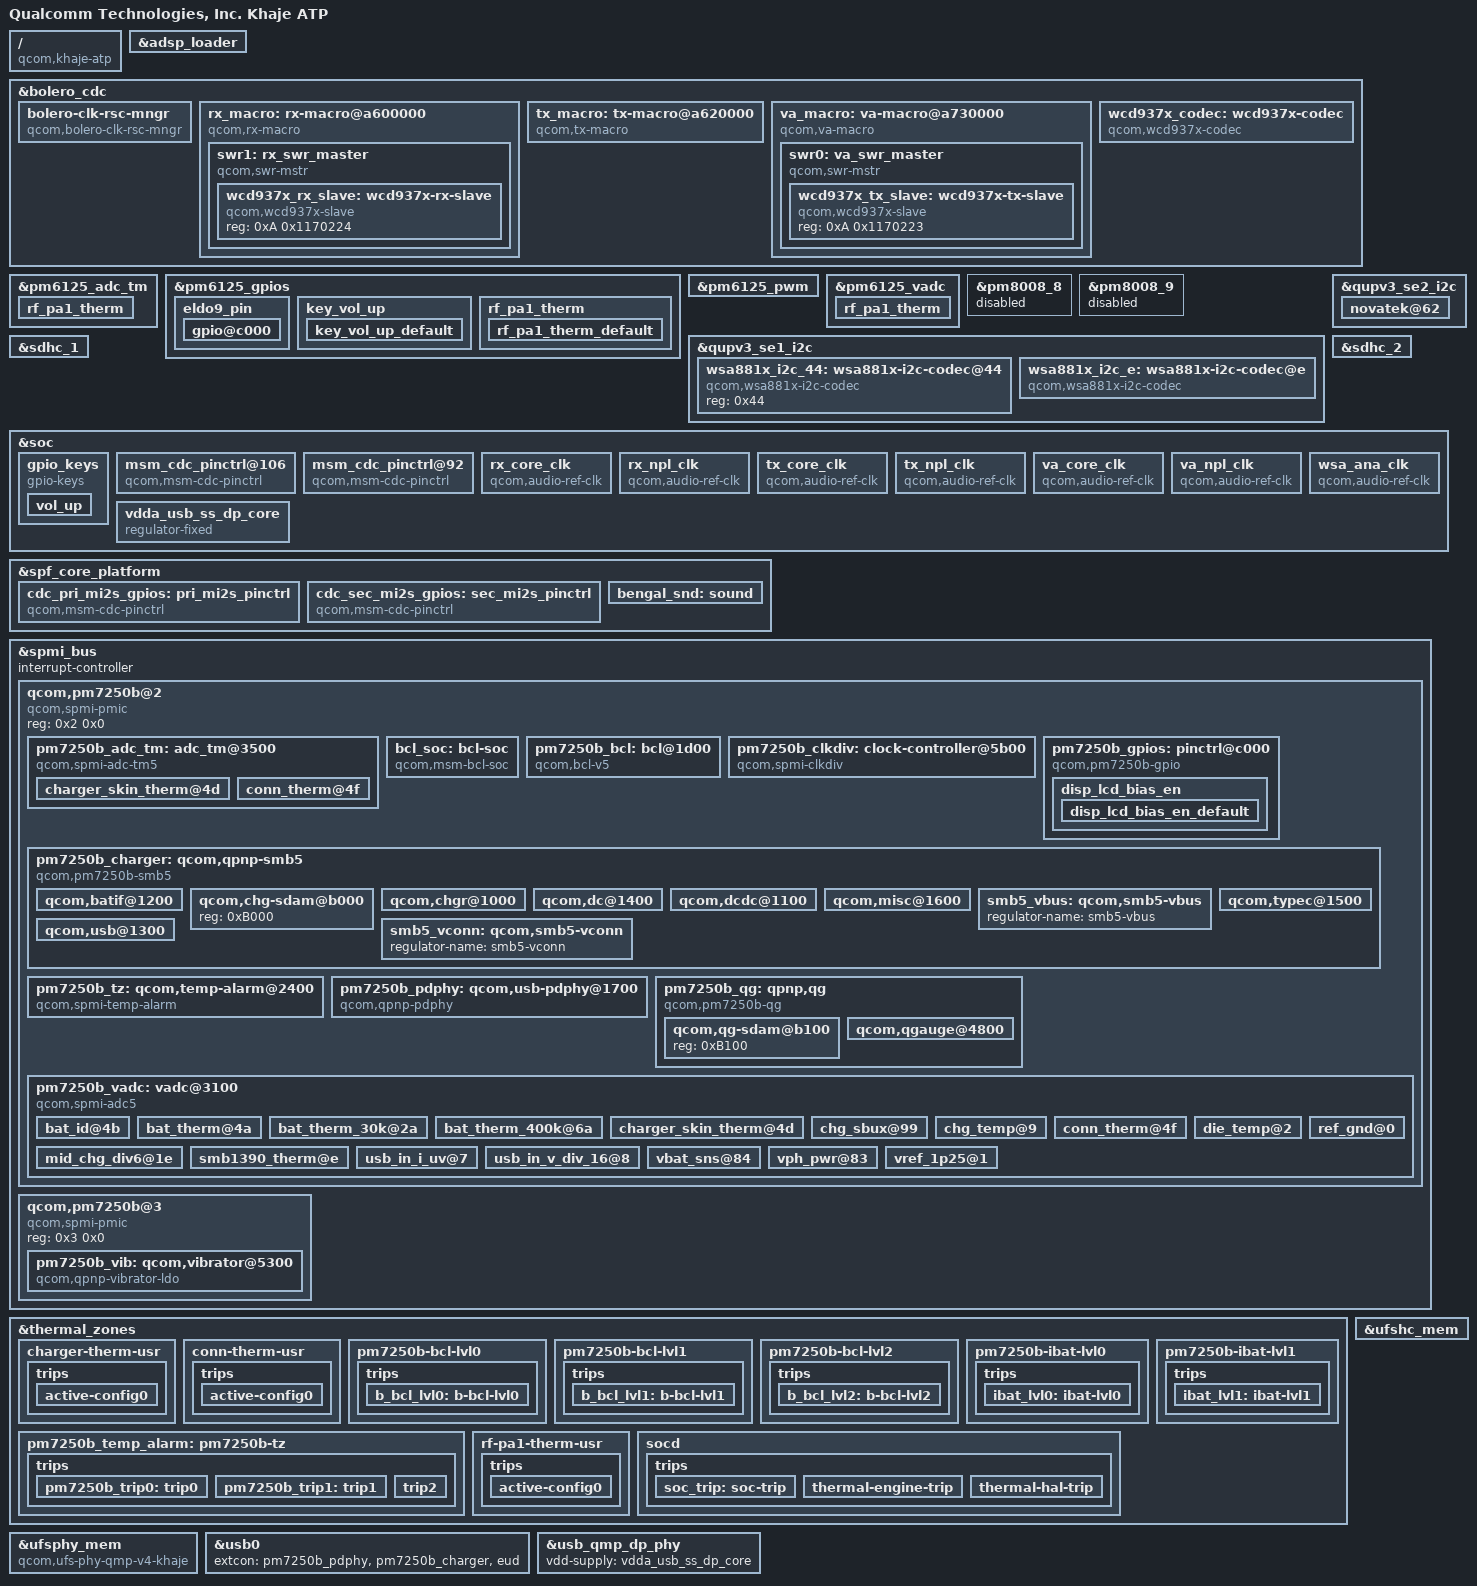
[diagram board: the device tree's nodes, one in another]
/dts-v1/;

/ {
    compatible = "qcom,khaje-atp", "qcom,khaje", "qcom,atp";
    model = "Qualcomm Technologies, Inc. Khaje ATP";
    qcom,board-id = <0x21 0x0>;
    qcom,msm-id = <0x24A 0x10000>;
    qcom,pmic-id = <0x2D 0x2E 0x0 0x0>;
};

&adsp_loader {
    adsp-fw-bit-values = <0x1>;
    adsp-fw-names = "adsp2";
    nvmem-cell-names = "adsp_variant";
    nvmem-cells = <&adsp_variant>;
};

&bolero_cdc {
    qcom,bolero-version = <0x5>;
    qcom,num-macros = <0x3>;
    bolero-clk-rsc-mngr {
        clock-names = "tx_core_clk", "tx_npl_clk", "rx_core_clk", "rx_npl_clk", "va_core_clk", "va_npl_clk";
        clocks = <&clock_audio_tx_1 0x0 &clock_audio_tx_2 0x0 &clock_audio_rx_1 0x0 &clock_audio_rx_2 0x0 &clock_audio_va_1 0x0 &clock_audio_va_2 0x0>;
        compatible = "qcom,bolero-clk-rsc-mngr";
        qcom,fs-gen-sequence = <0x3000 0x1 0x1 0x3004 0x3 0x3 0x3004 0x3 0x1 0x3080 0x2 0x2>;
        qcom,rx_mclk_mode_muxsel = <0xA5640D8>;
        qcom,va_mclk_mode_muxsel = "\nz";
    };
    rx_macro: rx-macro@a600000 {
        clock-names = "rx_core_clk", "rx_npl_clk";
        clocks = <&clock_audio_rx_1 0x0 &clock_audio_rx_2 0x0>;
        compatible = "qcom,rx-macro";
        qcom,default-clk-id = <0x0>;
        qcom,rx-bcl-pmic-params = [00 04 3E];
        qcom,rx-swr-gpios = <&rx_swr_gpios>;
        qcom,rx_mclk_mode_muxsel = <0xA5640D8>;
        reg = <0xA600000 0x0>;
        swr1: rx_swr_master {
            #address-cells = <0x2>;
            #size-cells = <0x0>;
            clock-names = "lpass_audio_hw_vote";
            clocks = <&lpass_audio_hw_vote 0x0>;
            compatible = "qcom,swr-mstr";
            interrupt-names = "swr_master_irq";
            interrupts = <0x0 0x129 0x4>;
            qcom,disable-div2-clk-switch = <0x1>;
            qcom,mipi-sdw-block-packing-mode = <0x1>;
            qcom,swr-clock-stop-mode0 = <0x1>;
            qcom,swr-master-version = <0x1060000>;
            qcom,swr-num-dev = <0x1>;
            qcom,swr-num-ports = <0x5>;
            qcom,swr-port-mapping = <0x1 0xE 0x1 0x1 0xF 0x2 0x2 0x12 0x1 0x3 0x10 0x1 0x3 0x11 0x2 0x4 0x13 0x1 0x5 0x14 0x1 0x5 0x15 0x2>;
            qcom,swr_master_id = <0x2>;
            qcom,swrm-hctl-reg = <0xA6A9098>;
            swrm-io-base = <0xA610000 0x0>;
            wcd937x_rx_slave: wcd937x-rx-slave {
                compatible = "qcom,wcd937x-slave";
                reg = <0xA 0x1170224>;
            };
        };
    };
    tx_macro: tx-macro@a620000 {
        clock-names = "tx_core_clk", "tx_npl_clk";
        clocks = <&clock_audio_tx_1 0x0 &clock_audio_tx_2 0x0>;
        compatible = "qcom,tx-macro";
        qcom,is-used-swr-gpio = <0x0>;
        qcom,tx-dmic-sample-rate = <0x249F00>;
        reg = <0xA620000 0x0>;
    };
    va_macro: va-macro@a730000 {
        clock-names = "lpass_audio_hw_vote";
        clocks = <&lpass_audio_hw_vote 0x0>;
        compatible = "qcom,va-macro";
        qcom,default-clk-id = <0x0>;
        qcom,is-used-swr-gpio = <0x1>;
        qcom,va-clk-mux-select = <0x1>;
        qcom,va-dmic-sample-rate = <0x927C0>;
        qcom,va-island-mode-muxsel = "\nz";
        qcom,va-swr-gpios = <&va_swr_gpios>;
        reg = <0xA730000 0x0>;
        swr0: va_swr_master {
            #address-cells = <0x2>;
            #size-cells = <0x0>;
            clock-names = "lpass_audio_hw_vote";
            clocks = <&lpass_audio_hw_vote 0x0>;
            compatible = "qcom,swr-mstr";
            interrupt-names = "swr_master_irq", "swr_wake_irq";
            interrupts = <0x0 0x128 0x4 0x0 0x4F 0x4>;
            qcom,is-always-on = <0x1>;
            qcom,mipi-sdw-block-packing-mode = <0x1>;
            qcom,swr-clock-stop-mode0 = <0x1>;
            qcom,swr-master-version = <0x1060000>;
            qcom,swr-mstr-irq-wakeup-capable = <0x1>;
            qcom,swr-num-dev = <0x1>;
            qcom,swr-num-ports = <0x3>;
            qcom,swr-port-mapping = <0x1 0x2E 0x1 0x1 0x2F 0x2 0x1 0x30 0x4 0x1 0x31 0x8 0x2 0x32 0x1 0x2 0x33 0x2 0x2 0x34 0x4 0x2 0x35 0x8 0x3 0x36 0x1 0x3 0x37 0x2 0x3 0x38 0x4 0x3 0x39 0x8>;
            qcom,swr-wakeup-required = <0x1>;
            qcom,swr_master_id = <0x3>;
            qcom,swrm-hctl-reg = <0xA7EC100>;
            swrm-io-base = <0xA740000 0x0>;
            wcd937x_tx_slave: wcd937x-tx-slave {
                compatible = "qcom,wcd937x-slave";
                reg = <0xA 0x1170223>;
            };
        };
    };
    wcd937x_codec: wcd937x-codec {
        cdc-vdd-buck-supply = <&L14A>;
        cdc-vdd-rxtx-supply = <&L9A>;
        cdc-vddpx-supply = <&L9A>;
        compatible = "qcom,wcd937x-codec";
        qcom,cdc-micbias1-mv = <0x708>;
        qcom,cdc-micbias2-mv = <0x708>;
        qcom,cdc-micbias3-mv = <0x708>;
        qcom,cdc-on-demand-supplies = "cdc-vdd-buck";
        qcom,cdc-static-supplies = "cdc-vdd-rxtx", "cdc-vddpx";
        qcom,cdc-vdd-buck-current = <0x9EB10>;
        qcom,cdc-vdd-buck-voltage = <0x1B7740 0x1B7740>;
        qcom,cdc-vdd-rxtx-current = <0x2710>;
        qcom,cdc-vdd-rxtx-voltage = <0x1B7740 0x1B7740>;
        qcom,cdc-vddpx-current = <0x4E20>;
        qcom,cdc-vddpx-voltage = <0x1B7740 0x1B7740>;
        qcom,rx-slave = <&wcd937x_rx_slave>;
        qcom,rx_swr_ch_map = <0x0 0xE 0x1 0x0 0xE 0x0 0xF 0x2 0x0 0xF 0x1 0x12 0x1 0x0 0x12 0x2 0x10 0x1 0x0 0x10 0x2 0x11 0x2 0x0 0x11 0x3 0x13 0x1 0x0 0x13 0x4 0x14 0x1 0x0 0x14 0x4 0x15 0x2 0x0 0x15>;
        qcom,split-codec = <0x1>;
        qcom,swr-tx-port-params = <0x1 0x0 0x0 0x1 0x1 0x0 0x1 0x0 0x0 0x1 0x1 0x0 0x1 0x0 0x1 0x0 0x0 0x1 0x2 0x0 0x1 0x0 0x2 0x0 0x1 0x0 0x1 0x0 0x1 0x0 0x1 0x0>;
        qcom,tx-slave = <&wcd937x_tx_slave>;
        qcom,tx_swr_ch_map = <0x0 0x1E 0x1 0x493E00 0x2E 0x1 0x1F 0x1 0x493E00 0x32 0x1 0x20 0x2 0x493E00 0x33 0x2 0x22 0x1 0x0 0x31 0x2 0x23 0x2 0x0 0x32 0x2 0x1D 0x4 0x493E00 0x33 0x3 0x24 0x1 0x0 0x34 0x3 0x25 0x2 0x0 0x35 0x3 0x26 0x4 0x0 0x36 0x3 0x27 0x8 0x0 0x37>;
        qcom,wcd-rst-gpio-node = <&wcd937x_rst_gpio>;
    };
};

&pm6125_adc_tm {
    status = "ok";
    rf_pa1_therm {
        io-channels = <&pm6125_vadc 0x55>;
        qcom,hw-settle-time-us = <0xC8>;
        qcom,ratiometric;
        reg = <0x3>;
    };
};

&pm6125_gpios {
    eldo9_pin {
        gpio@c000 {
            bias-disable;
            function = "normal";
            output-high;
            pins = "gpio1";
            power-source = <0x0>;
            qcom,drive-strength = <0x2>;
        };
    };
    key_vol_up {
        key_vol_up_default: key_vol_up_default {
            bias-pull-up;
            function = "normal";
            input-enable;
            pins = "gpio5";
            power-source = <0x0>;
        };
    };
    rf_pa1_therm {
        rf_pa1_therm_default: rf_pa1_therm_default {
            bias-high-impedance;
            pins = "gpio7";
        };
    };
};

&pm6125_pwm {
    status = "okay";
};

&pm6125_vadc {
    pinctrl-0 = <&camera_therm_default &emmc_therm_default &rf_pa1_therm_default>;
    rf_pa1_therm {
        label = "rf_pa1_therm";
        qcom,hw-settle-time = <0xC8>;
        qcom,pre-scaling = <0x1 0x1>;
        qcom,ratiometric;
        reg = <0x55>;
    };
};

&pm8008_8 {
    status = "disabled";
};

&pm8008_9 {
    status = "disabled";
};

&qupv3_se1_i2c {
    wsa881x_i2c_44: wsa881x-i2c-codec@44 {
        compatible = "qcom,wsa881x-i2c-codec";
        reg = <0x44>;
    };
    wsa881x_i2c_e: wsa881x-i2c-codec@e {
        clock-names = "wsa_mclk";
        clocks = <&wsa881x_analog_clk 0x0>;
        compatible = "qcom,wsa881x-i2c-codec";
        qcom,wsa-analog-clk-gpio = <&wsa881x_analog_clk_gpio>;
        qcom,wsa-analog-reset-gpio = <&wsa881x_analog_reset_gpio>;
        qcom,wsa-prefix = "SpkrMono";
        reg = <0xE>;
    };
};

&qupv3_se2_i2c {
    status = "okay";
    novatek@62 {
        interrupt-parent = <&tlmm>;
        interrupts = <0x50 0x2008>;
        novatek,irq-gpio = <&tlmm 0x50 0x2008>;
        novatek,reset-gpio = <&tlmm 0x56 0x0>;
        pinctrl-0 = <&ts_int_active &ts_reset_active>;
        pinctrl-1 = <&ts_int_suspend &ts_reset_suspend>;
        pinctrl-2 = <&ts_release>;
        pinctrl-names = "pmx_ts_active", "pmx_ts_suspend", "pmx_ts_release";
        reg = <0x62>;
        status = "ok";
    };
};

&sdhc_1 {
    pinctrl-0 = <&sdc1_on>;
    pinctrl-1 = <&sdc1_off>;
    pinctrl-names = "active", "sleep";
    qcom,vdd-current-level = <0x0 0x8B290>;
    qcom,vdd-io-always-on;
    qcom,vdd-io-current-level = <0x0 0x4F588>;
    qcom,vdd-io-lpm-sup;
    qcom,vdd-io-voltage-level = <0x1B7740 0x1B7740>;
    qcom,vdd-voltage-level = <0x2D2A80 0x2D2A80>;
    status = "ok";
    vdd-io-supply = <&L11A>;
    vdd-supply = <&L24A>;
};

&sdhc_2 {
    cd-gpios = <&tlmm 0x58 0x1>;
    pinctrl-0 = <&sdc2_on>;
    pinctrl-1 = <&sdc2_off>;
    pinctrl-names = "active", "sleep";
    qcom,vdd-current-level = <0x0 0xC3500>;
    qcom,vdd-io-bias-current-level = <0x0 0x1770>;
    qcom,vdd-io-bias-voltage-level = <0x132A40 0x132A40>;
    qcom,vdd-io-current-level = <0x0 0x55F0>;
    qcom,vdd-io-voltage-level = <0x1B7740 0x2D2A80>;
    qcom,vdd-voltage-level = <0x2D2A80 0x2D2A80>;
    status = "ok";
    vdd-io-bias-supply = <&L7A>;
    vdd-io-supply = <&L5A>;
    vdd-supply = <&L22A>;
};

&soc {
    gpio_keys {
        compatible = "gpio-keys";
        label = "gpio-keys";
        pinctrl-0 = <&key_vol_up_default>;
        pinctrl-names = "default";
        vol_up {
            debounce-interval = <0xF>;
            gpio-key,wakeup;
            gpios = <&pm6125_gpios 0x5 0x1>;
            label = "volume_up";
            linux,can-disable;
            linux,code = <0x73>;
            linux,input-type = <0x1>;
        };
    };
    msm_cdc_pinctrl@106 {
        #gpio-cells = <0x0>;
        compatible = "qcom,msm-cdc-pinctrl";
        pinctrl-0 = <&spkr_1_sd_n_active>;
        pinctrl-1 = <&spkr_1_sd_n_sleep>;
        pinctrl-names = "aud_active", "aud_sleep";
    };
    msm_cdc_pinctrl@92 {
        #gpio-cells = <0x0>;
        compatible = "qcom,msm-cdc-pinctrl";
        pinctrl-0 = <&wcd937x_reset_active>;
        pinctrl-1 = <&wcd937x_reset_sleep>;
        pinctrl-names = "aud_active", "aud_sleep";
    };
    rx_core_clk {
        #clock-cells = <0x1>;
        compatible = "qcom,audio-ref-clk";
        qcom,codec-ext-clk-src = <0x5>;
        qcom,codec-lpass-clk-id = <0x30E>;
        qcom,codec-lpass-ext-clk-freq = <0x1588800>;
    };
    rx_npl_clk {
        #clock-cells = <0x1>;
        compatible = "qcom,audio-ref-clk";
        qcom,codec-ext-clk-src = <0x6>;
        qcom,codec-lpass-clk-id = <0x30F>;
        qcom,codec-lpass-ext-clk-freq = <0x1588800>;
    };
    tx_core_clk {
        #clock-cells = <0x1>;
        compatible = "qcom,audio-ref-clk";
        qcom,codec-ext-clk-src = <0x7>;
        qcom,codec-lpass-clk-id = <0x30C>;
        qcom,codec-lpass-ext-clk-freq = <0x124F800>;
    };
    tx_npl_clk {
        #clock-cells = <0x1>;
        compatible = "qcom,audio-ref-clk";
        qcom,codec-ext-clk-src = <0x8>;
        qcom,codec-lpass-clk-id = <0x30D>;
        qcom,codec-lpass-ext-clk-freq = <0x124F800>;
    };
    va_core_clk {
        #clock-cells = <0x1>;
        compatible = "qcom,audio-ref-clk";
        qcom,codec-ext-clk-src = <0x2>;
        qcom,codec-lpass-clk-id = <0x307>;
        qcom,codec-lpass-ext-clk-freq = <0x124F800>;
    };
    va_npl_clk {
        #clock-cells = <0x1>;
        compatible = "qcom,audio-ref-clk";
        qcom,codec-ext-clk-src = <0xA>;
        qcom,codec-lpass-clk-id = <0x308>;
        qcom,codec-lpass-ext-clk-freq = <0x124F800>;
    };
    vdda_usb_ss_dp_core {
        compatible = "regulator-fixed";
        enable-active-high;
        gpio = <&pm6125_gpios 0x1 0x0>;
        pinctrl-0 = <&usb_eldo9>;
        pinctrl-names = "default";
        regulator-max-microvolt = <0xD6D80>;
        regulator-min-microvolt = <0xD6D80>;
        regulator-name = "vdd_supply";
    };
    wsa_ana_clk {
        #clock-cells = <0x1>;
        compatible = "qcom,audio-ref-clk";
        qcom,codec-ext-clk-src = <0x3>;
        qcom,codec-lpass-clk-id = <0x301>;
        qcom,codec-lpass-ext-clk-freq = <0x927C00>;
    };
};

&spf_core_platform {
    cdc_pri_mi2s_gpios: pri_mi2s_pinctrl {
        #gpio-cells = <0x0>;
        compatible = "qcom,msm-cdc-pinctrl";
        pinctrl-0 = <&lpi_i2s1_sck_active &lpi_i2s1_ws_active &lpi_i2s1_sd0_active &lpi_i2s1_sd1_active>;
        pinctrl-1 = <&lpi_i2s1_sck_sleep &lpi_i2s1_ws_sleep &lpi_i2s1_sd0_sleep &lpi_i2s1_sd1_sleep>;
        pinctrl-names = "aud_active", "aud_sleep";
        qcom,lpi-gpios;
    };
    cdc_sec_mi2s_gpios: sec_mi2s_pinctrl {
        #gpio-cells = <0x0>;
        compatible = "qcom,msm-cdc-pinctrl";
        pinctrl-0 = <&lpi_i2s2_sck_active &lpi_i2s2_ws_active &lpi_i2s2_sd0_active &lpi_i2s2_sd1_active>;
        pinctrl-1 = <&lpi_i2s2_sck_sleep &lpi_i2s2_ws_sleep &lpi_i2s2_sd0_sleep &lpi_i2s2_sd1_sleep>;
        pinctrl-names = "aud_active", "aud_sleep";
        qcom,lpi-gpios;
    };
    bengal_snd: sound {
        asoc-codec = <&stub_codec &bolero_cdc &wcd937x_codec &wsa881x_i2c_e>;
        asoc-codec-names = "msm-stub-codec.1", "bolero-codec", "wcd937x_codec", "wsa-codec0";
        nvmem-cell-names = "adsp_variant";
        nvmem-cells = <&adsp_variant>;
        qcom,audio-routing = "AMIC1", "Analog Mic1", "AMIC1", "MIC BIAS1", "AMIC2", "Analog Mic2", "AMIC2", "MIC BIAS2", "AMIC3", "Analog Mic3", "AMIC3", "MIC BIAS3", "TX DMIC0", "Digital Mic0", "TX DMIC0", "MIC BIAS1", "TX DMIC1", "Digital Mic1", "TX DMIC1", "MIC BIAS1", "TX DMIC2", "Digital Mic2", "TX DMIC2", "MIC BIAS3", "TX DMIC3", "Digital Mic3", "TX DMIC3", "MIC BIAS3", "IN1_HPHL", "HPHL_OUT", "IN2_HPHR", "HPHR_OUT", "IN3_AUX", "AUX_OUT", "RX_TX DEC0_INP", "TX DEC0 MUX", "RX_TX DEC1_INP", "TX DEC1 MUX", "RX_TX DEC2_INP", "TX DEC2 MUX", "RX_TX DEC3_INP", "TX DEC3 MUX", "SpkrMono WSA_IN", "AUX", "TX SWR_INPUT", "WCD_TX_OUTPUT", "VA SWR_INPUT", "VA_SWR_CLK", "VA SWR_INPUT", "WCD_TX_OUTPUT", "TX_AIF1 CAP", "VA_SWR_CLK", "TX_AIF2 CAP", "VA_SWR_CLK", "TX_AIF3 CAP", "VA_SWR_CLK", "VA DMIC0", "Digital Mic0", "VA DMIC1", "Digital Mic1", "VA DMIC2", "Digital Mic2", "VA DMIC3", "Digital Mic3", "VA DMIC0", "VA MIC BIAS1", "VA DMIC1", "VA MIC BIAS1", "VA DMIC2", "VA MIC BIAS3", "VA DMIC3", "VA MIC BIAS3";
        qcom,cdc-dmic01-gpios = <&cdc_dmic01_gpios>;
        qcom,cdc-dmic23-gpios = <&cdc_dmic23_gpios>;
        qcom,model = "bengal-idp-snd-card";
        qcom,msm-mbhc-gnd-swh = <0x1>;
        qcom,msm-mbhc-hphl-swh = <0x1>;
        qcom,msm-mbhc-usbc-audio-supported = <0x0>;
        qcom,msm-mi2s-master = <0x1 0x1 0x1 0x1>;
        qcom,msm_audio_ssr_devs = <&audio_gpr &lpi_tlmm &bolero_cdc>;
        qcom,rxtx-bolero-codec = <0x1>;
        qcom,va-bolero-codec = <0x1>;
        qcom,wcn-btfm = <0x1>;
        qcom,wsa-aux-dev-prefix = "SpkrMono";
        qcom,wsa-max-devs = <0x1>;
    };
};

&spmi_bus {
    #address-cells = <0x2>;
    #interrupt-cells = <0x4>;
    #size-cells = <0x0>;
    interrupt-controller;
    qcom,pm7250b@2 {
        #address-cells = <0x1>;
        #size-cells = <0x0>;
        compatible = "qcom,spmi-pmic";
        reg = <0x2 0x0>;
        pm7250b_adc_tm: adc_tm@3500 {
            #address-cells = <0x1>;
            #size-cells = <0x0>;
            #thermal-sensor-cells = <0x1>;
            compatible = "qcom,spmi-adc-tm5";
            interrupt-names = "pm-adc-tm5";
            interrupts = <0x2 0x35 0x0 0x1>;
            reg = <0x3500>;
            status = "ok";
            charger_skin_therm@4d {
                io-channels = <&pm7250b_vadc 0x4D>;
                qcom,hw-settle-time-us = <0xC8>;
                qcom,ratiometric;
                reg = <0x0>;
            };
            conn_therm@4f {
                io-channels = <&pm7250b_vadc 0x4F>;
                qcom,hw-settle-time-us = <0xC8>;
                qcom,ratiometric;
                reg = <0x1>;
            };
        };
        bcl_soc: bcl-soc {
            #thermal-sensor-cells = <0x0>;
            compatible = "qcom,msm-bcl-soc";
        };
        pm7250b_bcl: bcl@1d00 {
            #thermal-sensor-cells = <0x1>;
            compatible = "qcom,bcl-v5";
            interrupt-names = "bcl-lvl0", "bcl-lvl1", "bcl-lvl2";
            interrupts = <0x2 0x1D 0x0 0x0 0x2 0x1D 0x1 0x0 0x2 0x1D 0x2 0x0>;
            reg = <0x1D00>;
        };
        pm7250b_clkdiv: clock-controller@5b00 {
            #clock-cells = <0x1>;
            assigned-clock-rates = <0x124F800>;
            assigned-clocks = <&pm7250b_clkdiv 0x1>;
            clock-names = "xo";
            clock-output-names = "pm7250b_div_clk1";
            clocks = <&rpmcc 0x0>;
            compatible = "qcom,spmi-clkdiv";
            qcom,num-clkdivs = <0x1>;
            reg = <0x5B00>;
        };
        pm7250b_gpios: pinctrl@c000 {
            #gpio-cells = <0x2>;
            #interrupt-cells = <0x2>;
            compatible = "qcom,pm7250b-gpio";
            gpio-controller;
            interrupt-controller;
            reg = <0xC000>;
            disp_lcd_bias_en {
                disp_lcd_bias_en_default: disp_lcd_bias_en_default {
                    bias-disable;
                    function = "func1";
                    input-disable;
                    output-enable;
                    pins = "gpio5";
                    power-source = <0x0>;
                    qcom,drive-strength = <0x2>;
                };
            };
        };
        pm7250b_charger: qcom,qpnp-smb5 {
            #address-cells = <0x1>;
            #cooling-cells = <0x2>;
            #size-cells = <0x1>;
            compatible = "qcom,pm7250b-smb5";
            depends-on-supply = <&pm7250b_vadc>;
            dpdm-supply = <&usb2_phy0>;
            io-channel-names = "usb_in_voltage", "usb_in_current", "chg_temp", "die_temp", "conn_temp", "sbux_res", "vph_voltage";
            io-channels = <&pm7250b_vadc 0x8 &pm7250b_vadc 0x7 &pm7250b_vadc 0x9 &pm7250b_vadc 0x6 &pm7250b_vadc 0x4F &pm7250b_vadc 0x99 &pm7250b_vadc 0x83>;
            qcom,auto-recharge-soc = <0x62>;
            qcom,batteryless-platform;
            qcom,charger-temp-max = <0x320>;
            qcom,hvdcp2-12v-max-icl-ua = <0x16E360>;
            qcom,hvdcp2-max-icl-ua = <0x1E8480>;
            qcom,sec-charger-config = <0x0>;
            qcom,step-charging-enable;
            qcom,suspend-input-on-debug-batt;
            qcom,sw-jeita-enable;
            qcom,thermal-mitigation = <0x5ACA30 0x5265C0 0x4C4B40 0x44AA20 0x3D0900 0x387520 0x3567E0 0x2DC6C0 0x2AB980 0x2625A0 0x1E8480 0x16E360 0xF4240 0xC3500 0x7A120 0x55730 0xC3500 0xC3500>;
            status = "ok";
            qcom,batif@1200 {
                interrupt-names = "bat-temp", "bat-ov", "bat-low", "bat-therm-or-id-missing", "bat-terminal-missing", "buck-oc", "vph-ov";
                interrupts = <0x2 0x12 0x0 0x1 0x2 0x12 0x2 0x3 0x2 0x12 0x3 0x3 0x2 0x12 0x4 0x3 0x2 0x12 0x5 0x3 0x2 0x12 0x6 0x3 0x2 0x12 0x7 0x3>;
                reg = <0x1200>;
            };
            qcom,chg-sdam@b000 {
                reg = <0xB000>;
            };
            qcom,chgr@1000 {
                interrupt-names = "chgr-error", "chg-state-change", "step-chg-state-change", "step-chg-soc-update-fail", "step-chg-soc-update-req", "fg-fvcal-qualified", "vph-alarm", "vph-drop-prechg";
                interrupts = <0x2 0x10 0x0 0x1 0x2 0x10 0x1 0x1 0x2 0x10 0x2 0x1 0x2 0x10 0x3 0x1 0x2 0x10 0x4 0x1 0x2 0x10 0x5 0x1 0x2 0x10 0x6 0x1 0x2 0x10 0x7 0x1>;
                reg = <0x1000>;
            };
            qcom,dc@1400 {
                interrupt-names = "dcin-vashdn", "dcin-uv", "dcin-ov", "dcin-plugin", "dcin-revi", "dcin-pon", "dcin-en";
                interrupts = <0x2 0x14 0x1 0x3 0x2 0x14 0x2 0x3 0x2 0x14 0x3 0x3 0x2 0x14 0x4 0x3 0x2 0x14 0x5 0x3 0x2 0x14 0x6 0x1 0x2 0x14 0x7 0x1>;
                reg = <0x1400>;
            };
            qcom,dcdc@1100 {
                interrupt-names = "otg-fail", "otg-oc-disable-sw", "otg-oc-hiccup", "bsm-active", "high-duty-cycle", "input-current-limiting", "concurrent-mode-disable", "switcher-power-ok";
                interrupts = <0x2 0x11 0x0 0x1 0x2 0x11 0x1 0x1 0x2 0x11 0x2 0x1 0x2 0x11 0x3 0x3 0x2 0x11 0x4 0x3 0x2 0x11 0x5 0x3 0x2 0x11 0x6 0x1 0x2 0x11 0x7 0x3>;
                reg = <0x1100>;
            };
            qcom,misc@1600 {
                interrupt-names = "wdog-snarl", "wdog-bark", "aicl-fail", "aicl-done", "smb-en", "imp-trigger", "temp-change", "temp-change-smb";
                interrupts = <0x2 0x16 0x0 0x1 0x2 0x16 0x1 0x1 0x2 0x16 0x2 0x1 0x2 0x16 0x3 0x1 0x2 0x16 0x4 0x3 0x2 0x16 0x5 0x1 0x2 0x16 0x6 0x1 0x2 0x16 0x7 0x1>;
                reg = <0x1600>;
            };
            smb5_vbus: qcom,smb5-vbus {
                regulator-name = "smb5-vbus";
            };
            smb5_vconn: qcom,smb5-vconn {
                regulator-name = "smb5-vconn";
            };
            qcom,typec@1500 {
                interrupt-names = "typec-or-rid-detect-change", "typec-vpd-detect", "typec-cc-state-change", "typec-vconn-oc", "typec-vbus-change", "typec-attach-detach", "typec-legacy-cable-detect", "typec-try-snk-src-detect";
                interrupts = <0x2 0x15 0x0 0x1 0x2 0x15 0x1 0x1 0x2 0x15 0x2 0x1 0x2 0x15 0x3 0x1 0x2 0x15 0x4 0x1 0x2 0x15 0x5 0x1 0x2 0x15 0x6 0x1 0x2 0x15 0x7 0x1>;
                reg = <0x1500>;
            };
            qcom,usb@1300 {
                interrupt-names = "usbin-collapse", "usbin-vashdn", "usbin-uv", "usbin-ov", "usbin-plugin", "usbin-revi-change", "usbin-src-change", "usbin-icl-change";
                interrupts = <0x2 0x13 0x0 0x3 0x2 0x13 0x1 0x3 0x2 0x13 0x2 0x3 0x2 0x13 0x3 0x3 0x2 0x13 0x4 0x3 0x2 0x13 0x5 0x3 0x2 0x13 0x6 0x1 0x2 0x13 0x7 0x1>;
                reg = <0x1300>;
            };
        };
        pm7250b_tz: qcom,temp-alarm@2400 {
            #thermal-sensor-cells = <0x0>;
            compatible = "qcom,spmi-temp-alarm";
            interrupts = <0x2 0x24 0x0 0x3>;
            io-channel-names = "thermal";
            io-channels = <&pm7250b_vadc 0x6>;
            qcom,temperature-threshold-set = <0x1>;
            reg = <0x2400>;
        };
        pm7250b_pdphy: qcom,usb-pdphy@1700 {
            #io-channel-cells = <0x1>;
            compatible = "qcom,qpnp-pdphy";
            interrupt-names = "sig-tx", "sig-rx", "msg-tx", "msg-rx", "msg-tx-failed", "msg-tx-discarded", "msg-rx-discarded", "fr-swap";
            interrupts = <0x2 0x17 0x0 0x1 0x2 0x17 0x1 0x1 0x2 0x17 0x2 0x1 0x2 0x17 0x3 0x1 0x2 0x17 0x4 0x1 0x2 0x17 0x5 0x1 0x2 0x17 0x6 0x1 0x2 0x17 0x7 0x1>;
            qcom,default-sink-caps = <0x1388 0xBB8 0x2328 0xBB8 0x2EE0 0x8CA>;
            reg = <0x1700>;
            vbus-supply = <&smb5_vbus>;
            vconn-supply = <&smb5_vconn>;
            vdd-pdphy-supply = <&L15A>;
        };
        pm7250b_qg: qpnp,qg {
            #address-cells = <0x1>;
            #size-cells = <0x1>;
            compatible = "qcom,pm7250b-qg";
            depends-on-supply = <&pm6125_rtc>;
            io-channel-names = "batt-therm", "batt-id";
            io-channels = <&pm7250b_vadc 0x2A &pm7250b_vadc 0x4B>;
            qcom,cl-feedback-on;
            qcom,hold-soc-while-full;
            qcom,linearize-soc;
            qcom,qg-iterm-ma = <0x96>;
            qcom,s3-entry-fifo-length = <0x2>;
            qcom,soc_decimal_rate = <0x0 0x20 0xA 0x1E 0x14 0x1C 0x1E 0x1C 0x28 0x1C 0x32 0x1C 0x3C 0x1C 0x46 0x1C 0x50 0x1C 0x5A 0x1A 0x5F 0xA 0x63 0x5>;
            qcom,vbatt-cutoff-mv = <0xC80>;
            qcom,vbatt-empty-cold-mv = <0xBB8>;
            qcom,vbatt-empty-mv = <0xBB8>;
            qcom,vbatt-low-cold-mv = <0xE74>;
            qcom,vbatt-low-mv = <0xCE4>;
            status = "ok";
            qcom,qg-sdam@b100 {
                reg = <0xB100>;
                status = "okay";
            };
            qcom,qgauge@4800 {
                interrupt-names = "qg-batt-missing", "qg-vbat-low", "qg-vbat-empty", "qg-fifo-done", "qg-good-ocv";
                interrupts = <0x2 0x48 0x0 0x3 0x2 0x48 0x1 0x3 0x2 0x48 0x2 0x1 0x2 0x48 0x3 0x1 0x2 0x48 0x4 0x1>;
                reg = <0x4800>;
                status = "okay";
            };
        };
        pm7250b_vadc: vadc@3100 {
            #address-cells = <0x1>;
            #io-channel-cells = <0x1>;
            #size-cells = <0x0>;
            compatible = "qcom,spmi-adc5";
            interrupt-names = "eoc-int-en-set";
            interrupts = <0x2 0x31 0x0 0x1>;
            io-channel-ranges;
            qcom,adc-vdd-reference = <0x753>;
            reg = <0x3100>;
            reg-names = "adc5-usr-base";
            bat_id@4b {
                label = "bat_id";
                qcom,hw-settle-time = <0xC8>;
                qcom,pre-scaling = <0x1 0x1>;
                qcom,ratiometric;
                reg = <0x4B>;
            };
            bat_therm@4a {
                label = "bat_therm";
                qcom,hw-settle-time = <0xC8>;
                qcom,pre-scaling = <0x1 0x1>;
                qcom,ratiometric;
                reg = <0x4A>;
            };
            bat_therm_30k@2a {
                label = "bat_therm_30k";
                qcom,hw-settle-time = <0xC8>;
                qcom,pre-scaling = <0x1 0x1>;
                qcom,ratiometric;
                reg = <0x2A>;
            };
            bat_therm_400k@6a {
                label = "bat_therm_400k";
                qcom,hw-settle-time = <0xC8>;
                qcom,pre-scaling = <0x1 0x1>;
                qcom,ratiometric;
                reg = <0x6A>;
            };
            charger_skin_therm@4d {
                label = "charger_skin_therm";
                qcom,hw-settle-time = <0xC8>;
                qcom,pre-scaling = <0x1 0x1>;
                qcom,ratiometric;
                reg = <0x4D>;
            };
            chg_sbux@99 {
                label = "chg_sbux";
                qcom,pre-scaling = <0x1 0x3>;
                reg = <0x99>;
            };
            chg_temp@9 {
                label = "chg_temp";
                qcom,pre-scaling = <0x1 0x1>;
                reg = <0x9>;
            };
            conn_therm@4f {
                label = "conn_therm";
                qcom,hw-settle-time = <0xC8>;
                qcom,pre-scaling = <0x1 0x1>;
                qcom,ratiometric;
                reg = <0x4F>;
            };
            die_temp@2 {
                label = "die_temp";
                qcom,pre-scaling = <0x1 0x1>;
                reg = <0x6>;
            };
            mid_chg_div6@1e {
                label = "chg_mid";
                qcom,pre-scaling = <0x1 0x6>;
                reg = <0x1E>;
            };
            ref_gnd@0 {
                label = "ref_gnd";
                qcom,pre-scaling = <0x1 0x1>;
                reg = <0x0>;
            };
            smb1390_therm@e {
                label = "smb1390_therm";
                qcom,hw-settle-time = <0xC8>;
                qcom,pre-scaling = <0x1 0x1>;
                reg = <0xE>;
            };
            usb_in_i_uv@7 {
                label = "usb_in_i_uv";
                qcom,pre-scaling = <0x1 0x1>;
                reg = <0x7>;
            };
            usb_in_v_div_16@8 {
                label = "usb_in_v_div_16";
                qcom,pre-scaling = <0x1 0x10>;
                reg = <0x8>;
            };
            vbat_sns@84 {
                label = "vbat_sns";
                qcom,pre-scaling = <0x1 0x3>;
                reg = <0x84>;
            };
            vph_pwr@83 {
                label = "vph_pwr";
                qcom,pre-scaling = <0x1 0x3>;
                reg = <0x83>;
            };
            vref_1p25@1 {
                label = "vref_1p25";
                qcom,pre-scaling = <0x1 0x1>;
                reg = <0x1>;
            };
        };
    };
    qcom,pm7250b@3 {
        #address-cells = <0x1>;
        #size-cells = <0x0>;
        compatible = "qcom,spmi-pmic";
        reg = <0x3 0x0>;
        pm7250b_vib: qcom,vibrator@5300 {
            compatible = "qcom,qpnp-vibrator-ldo";
            qcom,disable-overdrive;
            qcom,vib-ldo-volt-uv = <0x2DC6C0>;
            reg = <0x5300>;
        };
    };
};

&thermal_zones {
    charger-therm-usr {
        polling-delay = <0x0>;
        polling-delay-passive = <0x0>;
        thermal-governor = "user_space";
        thermal-sensors = <&pm7250b_adc_tm 0x0>;
        wake-capable-sensor;
        trips {
            active-config0 {
                hysteresis = <0x3E8>;
                temperature = <0x1E848>;
                type = "passive";
            };
        };
    };
    conn-therm-usr {
        polling-delay = <0x0>;
        polling-delay-passive = <0x0>;
        thermal-governor = "user_space";
        thermal-sensors = <&pm7250b_adc_tm 0x1>;
        wake-capable-sensor;
        trips {
            active-config0 {
                hysteresis = <0x3E8>;
                temperature = <0x1E848>;
                type = "passive";
            };
        };
    };
    pm7250b-bcl-lvl0 {
        polling-delay = <0x0>;
        polling-delay-passive = <0x64>;
        thermal-sensors = <&pm7250b_bcl 0x5>;
        trips {
            b_bcl_lvl0: b-bcl-lvl0 {
                hysteresis = <0x1>;
                temperature = <0x1>;
                type = "passive";
            };
        };
    };
    pm7250b-bcl-lvl1 {
        polling-delay = <0x0>;
        polling-delay-passive = <0x64>;
        thermal-sensors = <&pm7250b_bcl 0x6>;
        trips {
            b_bcl_lvl1: b-bcl-lvl1 {
                hysteresis = <0x1>;
                temperature = <0x1>;
                type = "passive";
            };
        };
    };
    pm7250b-bcl-lvl2 {
        polling-delay = <0x0>;
        polling-delay-passive = <0x64>;
        thermal-sensors = <&pm7250b_bcl 0x7>;
        trips {
            b_bcl_lvl2: b-bcl-lvl2 {
                hysteresis = <0x1>;
                temperature = <0x1>;
                type = "passive";
            };
        };
    };
    pm7250b-ibat-lvl0 {
        polling-delay = <0x0>;
        polling-delay-passive = <0x0>;
        thermal-sensors = <&pm7250b_bcl 0x0>;
        trips {
            ibat_lvl0: ibat-lvl0 {
                hysteresis = <0xC8>;
                temperature = <0x157C>;
                type = "passive";
            };
        };
    };
    pm7250b-ibat-lvl1 {
        polling-delay = <0x0>;
        polling-delay-passive = <0x0>;
        thermal-sensors = <&pm7250b_bcl 0x1>;
        trips {
            ibat_lvl1: ibat-lvl1 {
                hysteresis = <0xC8>;
                temperature = <0x1770>;
                type = "passive";
            };
        };
    };
    pm7250b_temp_alarm: pm7250b-tz {
        polling-delay = <0x0>;
        polling-delay-passive = <0x64>;
        thermal-sensors = <&pm7250b_tz>;
        trips {
            pm7250b_trip0: trip0 {
                hysteresis = <0x0>;
                temperature = <0x17318>;
                type = "passive";
            };
            pm7250b_trip1: trip1 {
                hysteresis = <0x0>;
                temperature = <0x1C138>;
                type = "passive";
            };
            trip2 {
                hysteresis = <0x0>;
                temperature = <0x23668>;
                type = "passive";
            };
        };
    };
    rf-pa1-therm-usr {
        polling-delay = <0x0>;
        polling-delay-passive = <0x0>;
        thermal-governor = "user_space";
        thermal-sensors = <&pm6125_adc_tm 0x3>;
        wake-capable-sensor;
        trips {
            active-config0 {
                hysteresis = <0x3E8>;
                temperature = <0x1E848>;
                type = "passive";
            };
        };
    };
    socd {
        polling-delay = <0x0>;
        polling-delay-passive = <0x64>;
        trips {
            soc_trip: soc-trip {
                hysteresis = <0x0>;
                temperature = <0x5A>;
                type = "passive";
            };
            thermal-engine-trip {
                hysteresis = <0x0>;
                temperature = <0x64>;
                type = "passive";
            };
            thermal-hal-trip {
                hysteresis = <0x0>;
                temperature = <0x64>;
                type = "passive";
            };
        };
    };
};

&ufshc_mem {
    qcom,vddp-ref-clk-max-microamp = <0x64>;
    qcom,vddp-ref-clk-supply = <&L18A>;
    reset-gpios = <&tlmm 0x71 0x1>;
    reset-names = "rst";
    resets = <&gcc 0x4>;
    status = "ok";
    vcc-max-microamp = "\f5";
    vcc-supply = <&L24A>;
    vccq2-max-microamp = "\f5";
    vccq2-supply = <&L11A>;
    vdd-hba-fixed-regulator;
    vdd-hba-supply = <&gcc_ufs_phy_gdsc>;
};

&ufsphy_mem {
    compatible = "qcom,ufs-phy-qmp-v4-khaje";
    status = "ok";
    vdda-phy-max-microamp = <0x14EC4>;
    vdda-phy-supply = <&L4A>;
    vdda-pll-max-microamp = <0x477C>;
    vdda-pll-supply = <&L18A>;
};

&usb0 {
    extcon = <&pm7250b_pdphy &pm7250b_charger &eud>;
};

&usb_qmp_dp_phy {
    vdd-supply = <&vdda_usb_ss_dp_core>;
};

